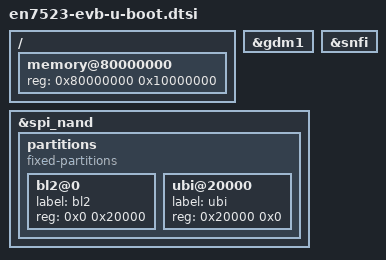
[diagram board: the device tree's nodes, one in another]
// SPDX-License-Identifier: GPL-2.0+

/ {
	/* When running as a first-stage bootloader this isn't filled in automatically */
	memory@80000000 {
		device_type = "memory";
		reg = <0x80000000 0x10000000>;
	};
};

#include "en7523-u-boot.dtsi"

&gdm1 {
	status = "okay";
};

&snfi {
	status = "okay";
};

&spi_nand {
	partitions {
		compatible = "fixed-partitions";
		#address-cells = <1>;
		#size-cells = <1>;

		bl2@0 {
			label = "bl2";
			reg = <0x0 0x20000>;
		};

		ubi@20000 {
			label = "ubi";
			reg = <0x20000 0x0>;
		};
	};
};
